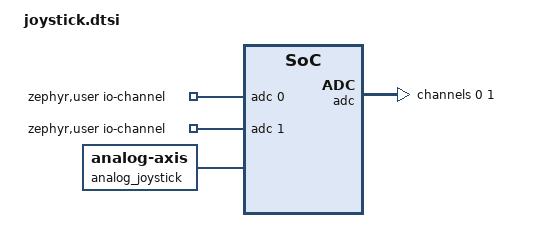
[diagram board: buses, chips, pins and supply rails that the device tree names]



#include <zephyr/dt-bindings/input/input-event-codes.h>
#include <zephyr/dt-bindings/adc/adc.h>
#include <zephyr/dt-bindings/adc/nrf-saadc.h>
#include <dt-bindings/zmk/keys.h>

/*
 * Typeglide joystick
 *
 * RKJX21224001
 *
 * X = AIN5
 * Y = AIN7
 *
 * ADC center measured at approximately 1866 raw counts.
 * Joystick swing is approximately +/-1707 counts.
 */

#define JOYSTICK_CENTER_X 1866
#define JOYSTICK_CENTER_Y 1866

#define JOYSTICK_SWING_X 1707
#define JOYSTICK_SWING_Y 1707

&adc {
    status = "okay";

    #address-cells = <1>;
    #size-cells = <0>;

    channel@0 {
        reg = <0>;

        zephyr,gain = "ADC_GAIN_1_6";
        zephyr,reference = "ADC_REF_INTERNAL";
        zephyr,acquisition-time = <ADC_ACQ_TIME_DEFAULT>;
        zephyr,resolution = <12>;
        zephyr,input-positive = <NRF_SAADC_AIN5>;
    };

    channel@1 {
        reg = <1>;

        zephyr,gain = "ADC_GAIN_1_6";
        zephyr,reference = "ADC_REF_INTERNAL";
        zephyr,acquisition-time = <ADC_ACQ_TIME_DEFAULT>;
        zephyr,resolution = <12>;
        zephyr,input-positive = <NRF_SAADC_AIN7>;
    };
};


/ {

    zephyr,user {
        io-channels = <&adc 0>, <&adc 1>;
    };

    analog_joystick: analog_joystick {
        compatible = "analog-axis";
        status = "okay";
        // status = "disabled";


        poll-period-ms = <20>;



        joystick_x: axis_x {
            io-channels = <&adc 0>;
//status = "disabled";
            in-min = <(JOYSTICK_CENTER_X - JOYSTICK_SWING_X)>;
            in-max = <(JOYSTICK_CENTER_X + JOYSTICK_SWING_X)>;

            zephyr,axis = <INPUT_ABS_X>;
        };

        joystick_y: axis_y {
            io-channels = <&adc 1>;
//status = "disabled";
            in-min = <(JOYSTICK_CENTER_Y - JOYSTICK_SWING_Y)>;
            in-max = <(JOYSTICK_CENTER_Y + JOYSTICK_SWING_Y)>;

            zephyr,axis = <INPUT_ABS_Y>;
        };
    };





};

/ {
    split_inputs {
        #address-cells = <1>;
        #size-cells = <0>;

        right_joystick_split: right_joystick_split@2 {
            compatible = "zmk,input-split";
            reg = <2>;
              device = <&analog_joystick>;
              //device = <&kscan0>;
               //status = "disabled";
               status = "okay";

        };
    };
};
